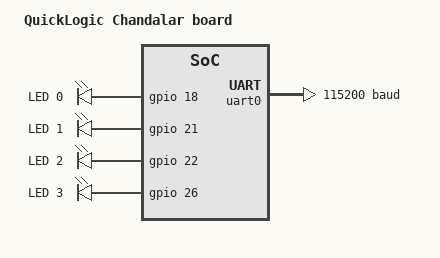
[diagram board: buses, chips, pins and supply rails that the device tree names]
/*
 * Copyright (c) 2020 Antmicro <www.antmicro.com>
 *
 * SPDX-License-Identifier: Apache-2.0
 */

/dts-v1/;
#include <quicklogic/quicklogic_eos_s3.dtsi>

/ {
	model = "QuickLogic Chandalar board";
	compatible = "quicklogic,eos_s3", "quicklogic,eos_s3x";

	chosen {
		zephyr,sram = &sram0;
		zephyr,console = &uart0;
		zephyr,shell-uart = &uart0;
		zephyr,uart-pipe = &uart0;
	};

	aliases {
		led0 = &led0;
		led1 = &led1;
		led2 = &led2;
		led3 = &led3;
	};

	leds {
		compatible = "gpio-leds";
		led0: led_0 {
			gpios = <&gpio 18 0>;
			label = "LED 0";
		};

		led1: led_1 {
			gpios = <&gpio 21 0>;
			label = "LED 1";
		};

		led2: led_2 {
			gpios = <&gpio 22 0>;
			label = "LED 2";
		};

		led3: led_3 {
			gpios = <&gpio 26 0>;
			label = "LED 3";
		};
	};
};

&cpu0 {
	clock-frequency = <61440000>;
};

&uart0 {
	status = "okay";
	current-speed = <115200>;
};
